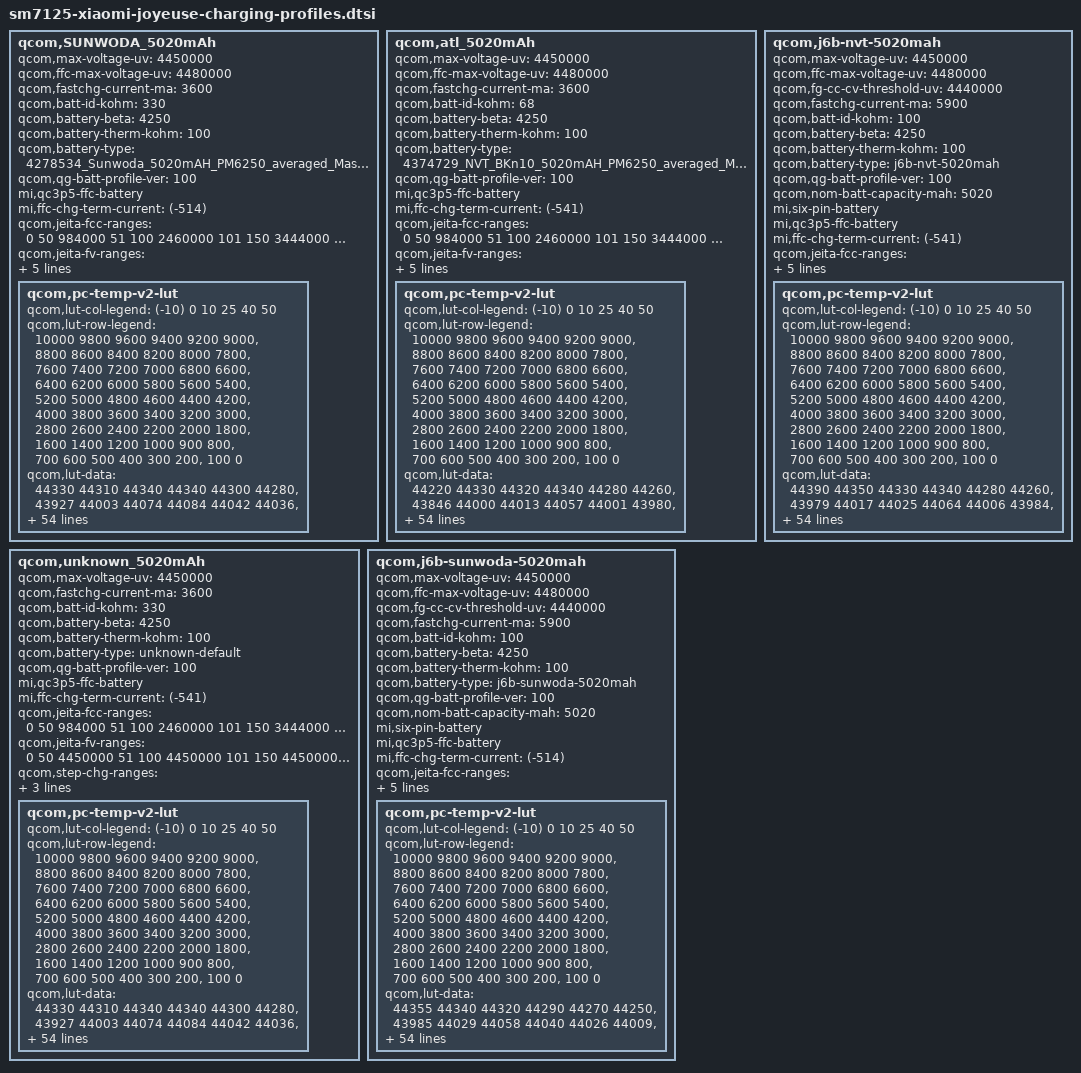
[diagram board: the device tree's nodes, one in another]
// SPDX-License-Identifier: GPL-2.0-only
/*
 * Copyright (c) 2019, The Linux Foundation. All rights reserved.
 * Copyright (C) 2020 XiaoMi, Inc.
 *
 * This program is free software; you can redistribute it and/or modify
 * it under the terms of the GNU General Public License version 2 and
 * only version 2 as published by the Free Software Foundation.
 *
 * This program is distributed in the hope that it will be useful,
 * but WITHOUT ANY WARRANTY; without even the implied warranty of
 * MERCHANTABILITY or FITNESS FOR A PARTICULAR PURPOSE.  See the
 * GNU General Public License for more details.
 */

qcom,SUNWODA_5020mAh {
	qcom,max-voltage-uv = <4450000>;
	qcom,ffc-max-voltage-uv = <4480000>;
	qcom,fastchg-current-ma = <3600>;
	qcom,batt-id-kohm = <330>;
	qcom,battery-beta = <4250>;
	qcom,battery-therm-kohm = <100>;
	qcom,battery-type =
		"4278534_Sunwoda_5020mAH_PM6250_averaged_MasterSlave_Nov7th2019";
	qcom,qg-batt-profile-ver = <100>;
	mi,qc3p5-ffc-battery;
	mi,ffc-chg-term-current = <(-514)>;
	qcom,jeita-fcc-ranges = <0   50   984000
				 51  100  2460000
				 101 150  3444000
				 151 450  3600000
				 451 600  2460000>;

	qcom,jeita-fv-ranges = <0   50   4450000
				51  100  4450000
				101 150  4450000
				151 450  4480000
				451 600  4100000>;

	qcom,step-chg-ranges = <3001000  4250000  3600000
				4250001  4430000  3300000
				4430001  4450000  3000000>;

	qcom,dynamic-fv-ranges = <0   100  4480000
				 101  200  4460000
				 201  300  4440000
				 301  400  4420000
				 401  500  4400000>;

	qcom,pc-temp-v2-lut {
		qcom,lut-col-legend = <(-10) 0 10 25 40 50>;
		qcom,lut-row-legend = <10000 9800 9600 9400 9200 9000>,
			<8800 8600 8400 8200 8000 7800>,
			<7600 7400 7200 7000 6800 6600>,
			<6400 6200 6000 5800 5600 5400>,
			<5200 5000 4800 4600 4400 4200>,
			<4000 3800 3600 3400 3200 3000>,
			<2800 2600 2400 2200 2000 1800>,
			<1600 1400 1200 1000 900 800>,
			<700 600 500 400 300 200>,
			<100 0>;
		qcom,lut-data = <44330 44310 44340 44340 44300 44280>,
			<43927 44003 44074 44084 44042 44036>,
			<43573 43720 43820 43839 43796 43800>,
			<43276 43463 43584 43608 43564 43573>,
			<43033 43236 43367 43393 43348 43357>,
			<42792 43005 43143 43171 43126 43134>,
			<42532 42756 42903 42933 42888 42896>,
			<42266 42500 42655 42688 42645 42651>,
			<41979 42242 42406 42441 42400 42406>,
			<41652 41981 42155 42192 42154 42159>,
			<41411 41722 41906 41946 41910 41914>,
			<41304 41459 41664 41703 41669 41673>,
			<41220 41208 41425 41463 41432 41435>,
			<41051 41015 41191 41229 41200 41204>,
			<40719 40871 40963 41002 40975 40979>,
			<40359 40705 40745 40781 40756 40760>,
			<40020 40441 40547 40566 40543 40547>,
			<39692 40131 40353 40359 40337 40341>,
			<39430 39869 40142 40164 40145 40149>,
			<39220 39641 39918 39981 39965 39970>,
			<39014 39421 39689 39778 39772 39775>,
			<38767 39200 39447 39533 39544 39545>,
			<38532 38985 39211 39286 39310 39308>,
			<38396 38792 39009 39075 39099 39098>,
			<38311 38614 38829 38885 38900 38901>,
			<38242 38448 38672 38726 38735 38738>,
			<38179 38275 38536 38594 38604 38606>,
			<38123 38120 38414 38479 38490 38492>,
			<38067 38036 38305 38373 38386 38388>,
			<38012 37986 38206 38277 38291 38292>,
			<37958 37944 38112 38188 38205 38206>,
			<37903 37904 38014 38105 38127 38129>,
			<37846 37867 37927 38028 38053 38055>,
			<37784 37823 37865 37957 37978 37980>,
			<37718 37775 37818 37890 37902 37905>,
			<37649 37723 37773 37820 37818 37821>,
			<37580 37669 37733 37747 37722 37723>,
			<37508 37611 37690 37670 37622 37619>,
			<37425 37539 37631 37590 37529 37523>,
			<37331 37451 37556 37505 37438 37428>,
			<37236 37350 37464 37415 37345 37333>,
			<37141 37232 37346 37319 37252 37238>,
			<37051 37106 37212 37199 37138 37126>,
			<36971 36985 37063 37052 36989 36980>,
			<36896 36880 36916 36930 36882 36874>,
			<36816 36784 36825 36879 36838 36832>,
			<36766 36726 36792 36866 36826 36817>,
			<36714 36661 36752 36846 36809 36799>,
			<36652 36595 36694 36811 36779 36765>,
			<36541 36493 36585 36722 36670 36647>,
			<36311 36322 36340 36407 36337 36307>,
			<35881 35966 35877 35885 35817 35764>,
			<35225 35364 35210 35200 35133 35048>,
			<34250 34460 34293 34227 34159 34056>,
			<32677 32962 32764 32652 32768 32603>,
			<30163 28489 27415 27358 27428 27387>;
	};
};

qcom,atl_5020mAh {
	qcom,max-voltage-uv = <4450000>;
	qcom,ffc-max-voltage-uv = <4480000>;
	qcom,fastchg-current-ma = <3600>;
	qcom,batt-id-kohm = <68>;
	qcom,battery-beta = <4250>;
	qcom,battery-therm-kohm = <100>;
	qcom,battery-type =
		"4374729_NVT_BKn10_5020mAH_PM6250_averaged_MasterSlave_Dec27th2019";
	qcom,qg-batt-profile-ver = <100>;
	mi,qc3p5-ffc-battery;
	mi,ffc-chg-term-current = <(-541)>;

	qcom,jeita-fcc-ranges = <0   50   984000
				 51  100  2460000
				 101 150  3444000
				 151 450  3600000
				 451 600  2460000>;

	qcom,jeita-fv-ranges = <0   50   4450000
				51  100  4450000
				101 150  4450000
				151 450  4480000
				451 600  4100000>;

	qcom,step-chg-ranges = <3001000  4250000  3600000
				4250001  4430000  3300000
				4430001  4450000  3000000>;

	qcom,dynamic-fv-ranges = <0   100  4480000
				 101  200  4460000
				 201  300  4440000
				 301  400  4420000
				 401  500  4400000>;

	qcom,pc-temp-v2-lut {
		qcom,lut-col-legend = <(-10) 0 10 25 40 50>;
		qcom,lut-row-legend = <10000 9800 9600 9400 9200 9000>,
			<8800 8600 8400 8200 8000 7800>,
			<7600 7400 7200 7000 6800 6600>,
			<6400 6200 6000 5800 5600 5400>,
			<5200 5000 4800 4600 4400 4200>,
			<4000 3800 3600 3400 3200 3000>,
			<2800 2600 2400 2200 2000 1800>,
			<1600 1400 1200 1000 900 800>,
			<700 600 500 400 300 200>,
			<100 0>;
		qcom,lut-data = <44220 44330 44320 44340 44280 44260>,
			<43846 44000 44013 44057 44001 43980>,
			<43513 43701 43733 43793 43739 43718>,
			<43232 43441 43482 43554 43500 43478>,
			<42999 43217 43263 43338 43283 43261>,
			<42771 42994 43039 43117 43062 43040>,
			<42514 42754 42798 42879 42826 42806>,
			<42248 42509 42550 42635 42584 42567>,
			<42008 42260 42302 42390 42343 42327>,
			<41792 42005 42053 42144 42099 42084>,
			<41586 41753 41808 41903 41859 41845>,
			<41390 41497 41570 41665 41622 41608>,
			<41202 41251 41338 41431 41389 41376>,
			<40989 41055 41111 41202 41160 41148>,
			<40736 40905 40890 40977 40938 40926>,
			<40459 40735 40677 40759 40723 40712>,
			<40159 40484 40477 40550 40517 40505>,
			<39832 40195 40280 40347 40319 40305>,
			<39546 39940 40081 40158 40134 40120>,
			<39320 39709 39880 39979 39958 39945>,
			<39116 39483 39664 39777 39766 39757>,
			<38910 39251 39413 39531 39534 39533>,
			<38704 39027 39163 39284 39297 39305>,
			<38536 38831 38960 39074 39090 39100>,
			<38415 38656 38783 38884 38900 38907>,
			<38317 38495 38626 38726 38742 38748>,
			<38238 38334 38486 38597 38614 38619>,
			<38174 38190 38359 38484 38504 38508>,
			<38115 38105 38239 38377 38400 38403>,
			<38056 38050 38127 38279 38304 38305>,
			<38000 38002 38034 38190 38217 38217>,
			<37943 37954 37956 38109 38141 38139>,
			<37887 37908 37893 38033 38068 38064>,
			<37828 37861 37850 37961 37997 37991>,
			<37768 37816 37818 37893 37927 37919>,
			<37705 37767 37782 37821 37846 37832>,
			<37637 37711 37740 37745 37746 37714>,
			<37563 37649 37692 37666 37641 37592>,
			<37484 37577 37629 37583 37544 37492>,
			<37393 37493 37549 37496 37448 37400>,
			<37292 37398 37451 37406 37355 37309>,
			<37194 37290 37318 37312 37268 37222>,
			<37099 37166 37170 37195 37158 37111>,
			<37014 37022 37006 37053 37013 36956>,
			<36945 36883 36850 36919 36889 36836>,
			<36877 36773 36748 36858 36839 36788>,
			<36840 36732 36709 36844 36830 36778>,
			<36793 36702 36665 36822 36815 36763>,
			<36742 36663 36618 36781 36790 36734>,
			<36679 36622 36519 36692 36704 36626>,
			<36584 36523 36278 36388 36388 36294>,
			<36412 36207 35819 35867 35884 35781>,
			<36107 35577 35149 35176 35223 35104>,
			<35532 34601 34139 34194 34286 34157>,
			<34689 33433 32559 32713 32910 32798>,
			<33552 31613 28186 27744 27717 27697>;
	};
};

qcom,unknown_5020mAh {
	qcom,max-voltage-uv = <4450000>;
	qcom,fastchg-current-ma = <3600>;
	qcom,batt-id-kohm = <330>;
	qcom,battery-beta = <4250>;
	qcom,battery-therm-kohm = <100>;
	qcom,battery-type =
		"unknown-default";
	qcom,qg-batt-profile-ver = <100>;
	mi,qc3p5-ffc-battery;
	mi,ffc-chg-term-current = <(-541)>;

	qcom,jeita-fcc-ranges = <0  50  984000
				51  100  2460000
				101 150  3444000
				151 450  3600000
				451 600  2460000>;

	qcom,jeita-fv-ranges = <0   50  4450000
				51  100  4450000
				101 150  4450000
				151 450  4480000
				451 600  4100000>;

	qcom,step-chg-ranges = <3001000  4250000  3600000
				4250001  4430000  3300000
				4430001  4450000  3000000>;

	qcom,dynamic-fv-ranges = <0   100  4480000
				 101  200  4460000
				 201  300  4440000
				 301  400  4420000
				 401  500  4400000>;

	qcom,pc-temp-v2-lut {
		qcom,lut-col-legend = <(-10) 0 10 25 40 50>;
		qcom,lut-row-legend = <10000 9800 9600 9400 9200 9000>,
			<8800 8600 8400 8200 8000 7800>,
			<7600 7400 7200 7000 6800 6600>,
			<6400 6200 6000 5800 5600 5400>,
			<5200 5000 4800 4600 4400 4200>,
			<4000 3800 3600 3400 3200 3000>,
			<2800 2600 2400 2200 2000 1800>,
			<1600 1400 1200 1000 900 800>,
			<700 600 500 400 300 200>,
			<100 0>;
		qcom,lut-data = <44330 44310 44340 44340 44300 44280>,
			<43927 44003 44074 44084 44042 44036>,
			<43573 43720 43820 43839 43796 43800>,
			<43276 43463 43584 43608 43564 43573>,
			<43033 43236 43367 43393 43348 43357>,
			<42792 43005 43143 43171 43126 43134>,
			<42532 42756 42903 42933 42888 42896>,
			<42266 42500 42655 42688 42645 42651>,
			<41979 42242 42406 42441 42400 42406>,
			<41652 41981 42155 42192 42154 42159>,
			<41411 41722 41906 41946 41910 41914>,
			<41304 41459 41664 41703 41669 41673>,
			<41220 41208 41425 41463 41432 41435>,
			<41051 41015 41191 41229 41200 41204>,
			<40719 40871 40963 41002 40975 40979>,
			<40359 40705 40745 40781 40756 40760>,
			<40020 40441 40547 40566 40543 40547>,
			<39692 40131 40353 40359 40337 40341>,
			<39430 39869 40142 40164 40145 40149>,
			<39220 39641 39918 39981 39965 39970>,
			<39014 39421 39689 39778 39772 39775>,
			<38767 39200 39447 39533 39544 39545>,
			<38532 38985 39211 39286 39310 39308>,
			<38396 38792 39009 39075 39099 39098>,
			<38311 38614 38829 38885 38900 38901>,
			<38242 38448 38672 38726 38735 38738>,
			<38179 38275 38536 38594 38604 38606>,
			<38123 38120 38414 38479 38490 38492>,
			<38067 38036 38305 38373 38386 38388>,
			<38012 37986 38206 38277 38291 38292>,
			<37958 37944 38112 38188 38205 38206>,
			<37903 37904 38014 38105 38127 38129>,
			<37846 37867 37927 38028 38053 38055>,
			<37784 37823 37865 37957 37978 37980>,
			<37718 37775 37818 37890 37902 37905>,
			<37649 37723 37773 37820 37818 37821>,
			<37580 37669 37733 37747 37722 37723>,
			<37508 37611 37690 37670 37622 37619>,
			<37425 37539 37631 37590 37529 37523>,
			<37331 37451 37556 37505 37438 37428>,
			<37236 37350 37464 37415 37345 37333>,
			<37141 37232 37346 37319 37252 37238>,
			<37051 37106 37212 37199 37138 37126>,
			<36971 36985 37063 37052 36989 36980>,
			<36896 36880 36916 36930 36882 36874>,
			<36816 36784 36825 36879 36838 36832>,
			<36766 36726 36792 36866 36826 36817>,
			<36714 36661 36752 36846 36809 36799>,
			<36652 36595 36694 36811 36779 36765>,
			<36541 36493 36585 36722 36670 36647>,
			<36311 36322 36340 36407 36337 36307>,
			<35881 35966 35877 35885 35817 35764>,
			<35225 35364 35210 35200 35133 35048>,
			<34250 34460 34293 34227 34159 34056>,
			<32677 32962 32764 32652 32768 32603>,
			<30163 28489 27415 27358 27428 27387>;
	};
};

qcom,j6b-nvt-5020mah {
    /* 4330536_LC_M524_ATL_5020mAH_PM6250_averaged_MasterSlave_Dec4th2019 */
	qcom,max-voltage-uv = <4450000>;
	qcom,ffc-max-voltage-uv = <4480000>;
	qcom,fg-cc-cv-threshold-uv = <4440000>;
	qcom,fastchg-current-ma = <5900>;
	qcom,batt-id-kohm = <100>;
	qcom,battery-beta = <4250>;
	qcom,battery-therm-kohm = <100>;
	qcom,battery-type = "j6b-nvt-5020mah";
	qcom,qg-batt-profile-ver = <100>;
	qcom,nom-batt-capacity-mah = <5020>;
	mi,six-pin-battery;
	mi,qc3p5-ffc-battery;
	mi,ffc-chg-term-current = <(-541)>;

	qcom,jeita-fcc-ranges = <0  50   900000
				51  100  2300000
				101 150  3300000
				151 450  5900000
				451 580  2300000>;

	qcom,jeita-fv-ranges = <0   50   4450000
				51  100  4450000
				101 150  4450000
				151 450  4480000
				451 580  4100000>;

	qcom,step-chg-ranges = <3001000  4250000  6000000
				4250001  4450000  4900000
				4450001  4480000  3900000>;

	qcom,pc-temp-v2-lut {
		qcom,lut-col-legend = <(-10) 0 10 25 40 50>;
		qcom,lut-row-legend = <10000 9800 9600 9400 9200 9000>,
			<8800 8600 8400 8200 8000 7800>,
			<7600 7400 7200 7000 6800 6600>,
			<6400 6200 6000 5800 5600 5400>,
			<5200 5000 4800 4600 4400 4200>,
			<4000 3800 3600 3400 3200 3000>,
			<2800 2600 2400 2200 2000 1800>,
			<1600 1400 1200 1000 900 800>,
			<700 600 500 400 300 200>,
			<100 0>;
		qcom,lut-data = <44390 44350 44330 44340 44280 44260>,
			<43979 44017 44025 44064 44006 43984>,
			<43621 43717 43746 43803 43748 43724>,
			<43329 43457 43496 43563 43510 43485>,
			<43096 43236 43278 43343 43292 43267>,
			<42867 43014 43055 43120 43071 43047>,
			<42609 42774 42813 42883 42835 42813>,
			<42348 42528 42565 42641 42594 42574>,
			<42117 42278 42318 42398 42353 42333>,
			<41916 42025 42071 42152 42109 42089>,
			<41713 41777 41827 41909 41868 41849>,
			<41480 41535 41586 41669 41630 41611>,
			<41234 41303 41350 41434 41397 41379>,
			<41006 41098 41121 41204 41168 41151>,
			<40807 40920 40900 40981 40945 40929>,
			<40587 40727 40686 40765 40730 40715>,
			<40278 40488 40484 40555 40523 40507>,
			<39907 40226 40285 40353 40325 40306>,
			<39607 39977 40088 40163 40138 40121>,
			<39375 39734 39892 39983 39961 39947>,
			<39166 39498 39679 39780 39768 39758>,
			<38954 39267 39420 39533 39539 39533>,
			<38750 39046 39163 39287 39306 39303>,
			<38588 38854 38962 39077 39098 39097>,
			<38458 38683 38790 38887 38903 38904>,
			<38351 38522 38636 38729 38743 38745>,
			<38269 38351 38496 38598 38615 38618>,
			<38202 38199 38369 38484 38504 38507>,
			<38139 38111 38250 38379 38400 38402>,
			<38080 38054 38139 38283 38304 38304>,
			<38024 38006 38045 38194 38218 38216>,
			<37967 37958 37965 38111 38142 38138>,
			<37911 37913 37900 38034 38070 38064>,
			<37852 37866 37855 37962 37999 37991>,
			<37791 37818 37822 37893 37929 37920>,
			<37726 37767 37784 37821 37846 37831>,
			<37657 37715 37742 37747 37746 37710>,
			<37583 37658 37694 37668 37642 37585>,
			<37501 37589 37629 37585 37545 37485>,
			<37410 37506 37548 37497 37450 37395>,
			<37313 37411 37448 37407 37358 37306>,
			<37214 37299 37321 37314 37270 37220>,
			<37114 37171 37174 37196 37160 37109>,
			<37028 37024 37004 37054 37014 36955>,
			<36955 36883 36853 36921 36893 36837>,
			<36888 36773 36756 36861 36842 36791>,
			<36852 36733 36717 36840 36832 36779>,
			<36804 36696 36675 36821 36818 36764>,
			<36753 36663 36620 36785 36790 36734>,
			<36690 36616 36520 36700 36709 36630>,
			<36601 36518 36273 36408 36394 36295>,
			<36420 36192 35813 35883 35890 35785>,
			<36108 35548 35151 35206 35228 35112>,
			<35493 34610 34146 34245 34285 34171>,
			<34574 33407 32576 32760 32858 32791>,
			<33783 31471 27814 27898 27864 27816>;
	};
};

qcom,j6b-sunwoda-5020mah {
	/* 4322231_LC_M524_Sunwoda_5020mAH_PM6250_averaged_MasterSlave_Dec20th2019 */
	qcom,max-voltage-uv = <4450000>;
	qcom,ffc-max-voltage-uv = <4480000>;
	qcom,fg-cc-cv-threshold-uv = <4440000>;
	qcom,fastchg-current-ma = <5900>;
	qcom,batt-id-kohm = <100>;
	qcom,battery-beta = <4250>;
	qcom,battery-therm-kohm = <100>;
	qcom,battery-type = "j6b-sunwoda-5020mah";
	qcom,qg-batt-profile-ver = <100>;
	qcom,nom-batt-capacity-mah = <5020>;
	mi,six-pin-battery;
	mi,qc3p5-ffc-battery;
	mi,ffc-chg-term-current = <(-514)>;

	qcom,jeita-fcc-ranges = <0  50   900000
				51  100  2300000
				101 150  3300000
				151 450  5900000
				451 580  2300000>;

	qcom,jeita-fv-ranges = <0   50   4450000
				51  100  4450000
				101 150  4450000
				151 450  4480000
				451 580  4100000>;

	qcom,step-chg-ranges = <3001000  4250000  6000000
				4250001  4450000  4900000
				4450001  4480000  3900000>;

	qcom,pc-temp-v2-lut {
		qcom,lut-col-legend = <(-10) 0 10 25 40 50>;
		qcom,lut-row-legend = <10000 9800 9600 9400 9200 9000>,
			<8800 8600 8400 8200 8000 7800>,
			<7600 7400 7200 7000 6800 6600>,
			<6400 6200 6000 5800 5600 5400>,
			<5200 5000 4800 4600 4400 4200>,
			<4000 3800 3600 3400 3200 3000>,
			<2800 2600 2400 2200 2000 1800>,
			<1600 1400 1200 1000 900 800>,
			<700 600 500 400 300 200>,
			<100 0>;
		qcom,lut-data = <44355 44340 44320 44290 44270 44250>,
			<43985 44029 44058 44040 44026 44009>,
			<43650 43745 43809 43799 43790 43776>,
			<43359 43493 43577 43569 43565 43552>,
			<43109 43273 43363 43351 43350 43339>,
			<42862 43050 43143 43129 43131 43120>,
			<42590 42805 42902 42889 42895 42886>,
			<42316 42549 42651 42642 42653 42645>,
			<42065 42291 42402 42397 42409 42403>,
			<41828 42029 42151 42154 42164 42159>,
			<41613 41768 41904 41913 41921 41916>,
			<41436 41494 41661 41673 41682 41677>,
			<41269 41232 41423 41436 41445 41441>,
			<41057 41048 41191 41205 41214 41211>,
			<40782 40931 40966 40980 40990 40986>,
			<40477 40790 40753 40762 40772 40767>,
			<40138 40515 40565 40550 40561 40556>,
			<39778 40156 40382 40344 40358 40352>,
			<39502 39873 40164 40148 40163 40158>,
			<39295 39648 39901 39967 39982 39978>,
			<39099 39436 39642 39771 39787 39785>,
			<38862 39216 39407 39522 39547 39549>,
			<38624 39002 39186 39253 39292 39300>,
			<38470 38804 38992 39041 39081 39092>,
			<38372 38618 38818 38870 38901 38912>,
			<38293 38450 38662 38722 38746 38756>,
			<38221 38290 38524 38591 38615 38624>,
			<38157 38147 38400 38476 38502 38508>,
			<38098 38062 38285 38368 38397 38403>,
			<38043 38012 38176 38267 38301 38306>,
			<37989 37970 38077 38175 38214 38216>,
			<37929 37926 37982 38094 38134 38136>,
			<37867 37883 37897 38019 38059 38059>,
			<37801 37838 37838 37948 37984 37980>,
			<37733 37792 37799 37880 37909 37898>,
			<37661 37742 37762 37812 37828 37809>,
			<37584 37685 37725 37739 37731 37700>,
			<37503 37623 37686 37662 37625 37583>,
			<37421 37551 37631 37582 37529 37479>,
			<37337 37471 37553 37501 37441 37387>,
			<37255 37378 37455 37412 37348 37293>,
			<37179 37264 37328 37306 37247 37190>,
			<37108 37133 37180 37184 37134 37077>,
			<37040 36997 37026 37040 36992 36936>,
			<36968 36875 36896 36925 36886 36833>,
			<36881 36788 36811 36870 36838 36788>,
			<36826 36751 36773 36852 36826 36775>,
			<36763 36714 36733 36832 36810 36759>,
			<36689 36669 36676 36795 36780 36728>,
			<36577 36585 36573 36708 36691 36621>,
			<36371 36391 36336 36413 36374 36275>,
			<35995 35997 35894 35911 35878 35770>,
			<35394 35373 35269 35245 35221 35101>,
			<34516 34482 34387 34317 34298 34172>,
			<33069 32970 32916 32764 32899 32759>,
			<28712 28026 28771 27555 28520 28438>;
	};
};
